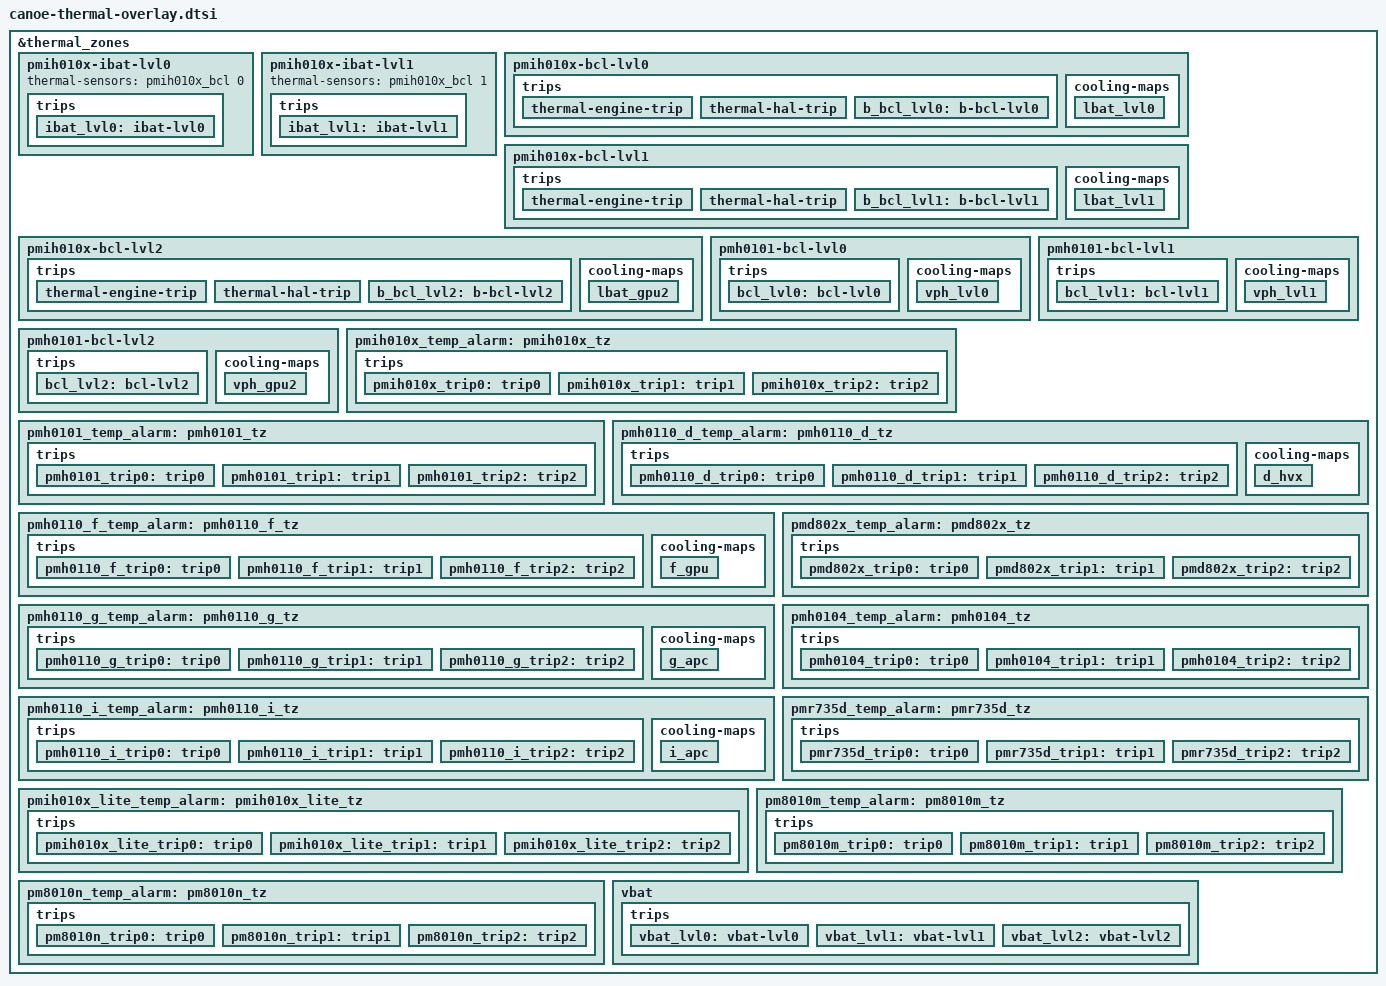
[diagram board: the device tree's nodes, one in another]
// SPDX-License-Identifier: BSD-3-Clause
/*
 * Copyright (c) Qualcomm Technologies, Inc. and/or its subsidiaries.
 */

#include <dt-bindings/thermal/thermal_qti.h>

&thermal_zones {
	pmih010x-ibat-lvl0 {
		thermal-sensors = <&pmih010x_bcl 0>;

		trips {
			ibat_lvl0:ibat-lvl0 {
				temperature = <13500>;
				hysteresis = <200>;
				type = "passive";
			};
		};
	};

	pmih010x-ibat-lvl1 {
		thermal-sensors = <&pmih010x_bcl 1>;

		trips {
			ibat_lvl1:ibat-lvl1 {
				temperature = <15000>;
				hysteresis = <200>;
				type = "passive";
			};
		};
	};

	pmih010x-bcl-lvl0 {
		polling-delay-passive = <100>;
		thermal-sensors = <&pmih010x_bcl 5>;

		trips {
			thermal-engine-trip {
				temperature = <100>;
				hysteresis = <0>;
				type = "passive";
			};

			thermal-hal-trip {
				temperature = <100>;
				hysteresis = <0>;
				type = "passive";
			};

			b_bcl_lvl0: b-bcl-lvl0 {
				temperature = <1>;
				hysteresis = <0>;
				type = "passive";
			};
		};

		cooling-maps {
			lbat_lvl0 {
				trip = <&b_bcl_lvl0>;
				cooling-device = <&modem_bcl 0 1>,
						 <&msm_gpu 0 1>;
			};
		};
	};

	pmih010x-bcl-lvl1 {
		polling-delay-passive = <100>;
		thermal-sensors = <&pmih010x_bcl 6>;

		trips {
			thermal-engine-trip {
				temperature = <100>;
				hysteresis = <0>;
				type = "passive";
			};

			thermal-hal-trip {
				temperature = <100>;
				hysteresis = <0>;
				type = "passive";
			};

			b_bcl_lvl1: b-bcl-lvl1 {
				temperature = <1>;
				hysteresis = <0>;
				type = "passive";
			};
		};

		cooling-maps {
			lbat_lvl1 {
				trip = <&b_bcl_lvl1>;
				cooling-device = <&modem_bcl 0 2>,
						 <&msm_gpu 0 2>;
			};
		};
	};

	pmih010x-bcl-lvl2 {
		polling-delay-passive = <100>;
		thermal-sensors = <&pmih010x_bcl 7>;

		trips {
			thermal-engine-trip {
				temperature = <100>;
				hysteresis = <0>;
				type = "passive";
			};

			thermal-hal-trip {
				temperature = <100>;
				hysteresis = <0>;
				type = "passive";
			};

			b_bcl_lvl2: b-bcl-lvl2 {
				temperature = <1>;
				hysteresis = <0>;
				type = "passive";
			};
		};

		cooling-maps {
			lbat_gpu2 {
				trip = <&b_bcl_lvl2>;
				cooling-device = <&msm_gpu 0 3>;
			};
		};
	};

	pmh0101-bcl-lvl0 {
		polling-delay-passive = <100>;
		thermal-sensors = <&pmh0101_bcl 5>;

		trips {
			bcl_lvl0: bcl-lvl0 {
				temperature = <1>;
				hysteresis = <0>;
				type = "passive";
			};
		};

		cooling-maps {
			vph_lvl0 {
				trip = <&bcl_lvl0>;
				cooling-device = <&modem_bcl 0 1>,
						 <&msm_gpu 0 1>;
			};
		};
	};

	pmh0101-bcl-lvl1 {
		polling-delay-passive = <100>;
		thermal-sensors = <&pmh0101_bcl 6>;

		trips {
			bcl_lvl1: bcl-lvl1 {
				temperature = <1>;
				hysteresis = <0>;
				type = "passive";
			};
		};

		cooling-maps {
			vph_lvl1 {
				trip = <&bcl_lvl1>;
				cooling-device = <&modem_bcl 0 2>,
						 <&msm_gpu 0 2>;
			};
		};
	};

	pmh0101-bcl-lvl2 {
		polling-delay-passive = <100>;
		thermal-sensors = <&pmh0101_bcl 7>;

		trips {
			bcl_lvl2: bcl-lvl2 {
				temperature = <1>;
				hysteresis = <0>;
				type = "passive";
			};
		};

		cooling-maps {
			vph_gpu2 {
				trip = <&bcl_lvl2>;
				cooling-device = <&msm_gpu 0 3>;
			};
		};
	};

	pmih010x_temp_alarm: pmih010x_tz {
		polling-delay-passive = <100>;
		thermal-sensors = <&pmih010x_tz>;

		trips {
			pmih010x_trip0: trip0 {
				temperature = <95000>;
				hysteresis = <0>;
				type = "passive";
			};

			pmih010x_trip1: trip1 {
				temperature = <115000>;
				hysteresis = <0>;
				type = "hot";
			};

			pmih010x_trip2: trip2 {
				temperature = <145000>;
				hysteresis = <0>;
				type = "critical";
			};
		};
	};

	pmh0101_temp_alarm: pmh0101_tz {
		polling-delay-passive = <100>;
		thermal-sensors = <&pmh0101_tz>;

		trips {
			pmh0101_trip0: trip0 {
				temperature = <95000>;
				hysteresis = <0>;
				type = "passive";
			};

			pmh0101_trip1: trip1 {
				temperature = <115000>;
				hysteresis = <0>;
				type = "hot";
			};

			pmh0101_trip2: trip2 {
				temperature = <145000>;
				hysteresis = <0>;
				type = "critical";
			};
		};
	};

	pmh0110_d_temp_alarm: pmh0110_d_tz {
		polling-delay-passive = <100>;
		thermal-sensors = <&pmh0110_d_tz>;

		trips {
			pmh0110_d_trip0: trip0 {
				temperature = <95000>;
				hysteresis = <0>;
				type = "passive";
			};

			pmh0110_d_trip1: trip1 {
				temperature = <115000>;
				hysteresis = <0>;
				type = "hot";
			};

			pmh0110_d_trip2: trip2 {
				temperature = <145000>;
				hysteresis = <0>;
				type = "critical";
			};
		};

		cooling-maps {
			d_hvx {
				trip = <&pmh0110_d_trip0>;
				cooling-device = <&cdsp_sw_hvx 5 THERMAL_NO_LIMIT
					&modem_lte_dsc 255 255
					&modem_nr_dsc 255 255>;
			};
		};
	};

	pmh0110_f_temp_alarm: pmh0110_f_tz {
		polling-delay-passive = <100>;
		thermal-sensors = <&pmh0110_f_tz>;

		trips {
			pmh0110_f_trip0: trip0 {
				temperature = <95000>;
				hysteresis = <0>;
				type = "passive";
			};

			pmh0110_f_trip1: trip1 {
				temperature = <115000>;
				hysteresis = <0>;
				type = "hot";
			};

			pmh0110_f_trip2: trip2 {
				temperature = <145000>;
				hysteresis = <0>;
				type = "critical";
			};
		};

		cooling-maps {
			f_gpu {
				trip = <&pmh0110_f_trip0>;
				cooling-device = <&msm_gpu 5 THERMAL_NO_LIMIT>;
			};
		};
	};

	pmh0110_g_temp_alarm: pmh0110_g_tz {
		polling-delay-passive = <100>;
		thermal-sensors = <&pmh0110_g_tz>;

		trips {
			pmh0110_g_trip0: trip0 {
				temperature = <95000>;
				hysteresis = <0>;
				type = "passive";
			};

			pmh0110_g_trip1: trip1 {
				temperature = <115000>;
				hysteresis = <0>;
				type = "hot";
			};

			pmh0110_g_trip2: trip2 {
				temperature = <145000>;
				hysteresis = <0>;
				type = "critical";
			};
		};

		cooling-maps {
			g_apc {
				trip = <&pmh0110_g_trip0>;
				cooling-device = <&APC0_MX_CX_PAUSE 1 1>;
			};
		};
	};

	pmh0110_i_temp_alarm: pmh0110_i_tz {
		polling-delay-passive = <100>;
		thermal-sensors = <&pmh0110_i_tz>;

		trips {
			pmh0110_i_trip0: trip0 {
				temperature = <95000>;
				hysteresis = <0>;
				type = "passive";
			};

			pmh0110_i_trip1: trip1 {
				temperature = <115000>;
				hysteresis = <0>;
				type = "hot";
			};

			pmh0110_i_trip2: trip2 {
				temperature = <145000>;
				hysteresis = <0>;
				type = "critical";
			};
		};

		cooling-maps {
			i_apc {
				trip = <&pmh0110_i_trip0>;
				cooling-device = <&APC1_MX_CX_PAUSE 1 1>;
			};
		};
	};

	pmd802x_temp_alarm: pmd802x_tz {
		polling-delay-passive = <100>;
		thermal-sensors = <&pmd802x_tz>;

		trips {
			pmd802x_trip0: trip0 {
				temperature = <95000>;
				hysteresis = <0>;
				type = "passive";
			};

			pmd802x_trip1: trip1 {
				temperature = <115000>;
				hysteresis = <0>;
				type = "hot";
			};

			pmd802x_trip2: trip2 {
				temperature = <145000>;
				hysteresis = <0>;
				type = "critical";
			};
		};
	};

	pmih010x_lite_temp_alarm: pmih010x_lite_tz {
		polling-delay-passive = <100>;
		thermal-sensors = <&pmih010x_lite_tz>;

		trips {
			pmih010x_lite_trip0: trip0 {
				temperature = <125000>;
				hysteresis = <0>;
				type = "passive";
			};

			pmih010x_lite_trip1: trip1 {
				temperature = <135000>;
				hysteresis = <0>;
				type = "hot";
			};

			pmih010x_lite_trip2: trip2 {
				temperature = <145000>;
				hysteresis = <0>;
				type = "critical";
			};
		};
	};

	pmh0104_temp_alarm: pmh0104_tz {
		polling-delay-passive = <100>;
		thermal-sensors = <&pmh0104_tz>;

		trips {
			pmh0104_trip0: trip0 {
				temperature = <95000>;
				hysteresis = <0>;
				type = "passive";
			};

			pmh0104_trip1: trip1 {
				temperature = <115000>;
				hysteresis = <0>;
				type = "hot";
			};

			pmh0104_trip2: trip2 {
				temperature = <145000>;
				hysteresis = <0>;
				type = "critical";
			};
		};
	};

	pmr735d_temp_alarm: pmr735d_tz {
		polling-delay-passive = <100>;
		thermal-sensors = <&pmr735d_tz>;

		trips {
			pmr735d_trip0: trip0 {
				temperature = <95000>;
				hysteresis = <0>;
				type = "passive";
			};

			pmr735d_trip1: trip1 {
				temperature = <115000>;
				hysteresis = <0>;
				type = "hot";
			};

			pmr735d_trip2: trip2 {
				temperature = <145000>;
				hysteresis = <0>;
				type = "critical";
			};
		};
	};

	pm8010m_temp_alarm: pm8010m_tz {
		polling-delay-passive = <100>;
		thermal-sensors = <&pm8010m_tz>;

		trips {
			pm8010m_trip0: trip0 {
				temperature = <95000>;
				hysteresis = <0>;
				type = "passive";
			};

			pm8010m_trip1: trip1 {
				temperature = <115000>;
				hysteresis = <0>;
				type = "hot";
			};

			pm8010m_trip2: trip2 {
				temperature = <145000>;
				hysteresis = <0>;
				type = "critical";
			};
		};
	};

	pm8010n_temp_alarm: pm8010n_tz {
		polling-delay-passive = <100>;
		thermal-sensors = <&pm8010n_tz>;

		trips {
			pm8010n_trip0: trip0 {
				temperature = <95000>;
				hysteresis = <0>;
				type = "passive";
			};

			pm8010n_trip1: trip1 {
				temperature = <115000>;
				hysteresis = <0>;
				type = "hot";
			};

			pm8010n_trip2: trip2 {
				temperature = <145000>;
				hysteresis = <0>;
				type = "critical";
			};
		};
	};

	vbat {
		polling-delay-passive = <0>;
		polling-delay = <0>;
		thermal-sensors = <&pmih010x_bcl 2>;

		trips {
			vbat_lvl0:vbat-lvl0 {
				temperature = <2800>;
				hysteresis = <100>;
				type = "passive";
			};

			vbat_lvl1:vbat-lvl1 {
				temperature = <2600>;
				hysteresis = <100>;
				type = "passive";
			};

			vbat_lvl2:vbat-lvl2 {
				temperature = <2300>;
				hysteresis = <100>;
				type = "passive";
			};
		};
	};
};
